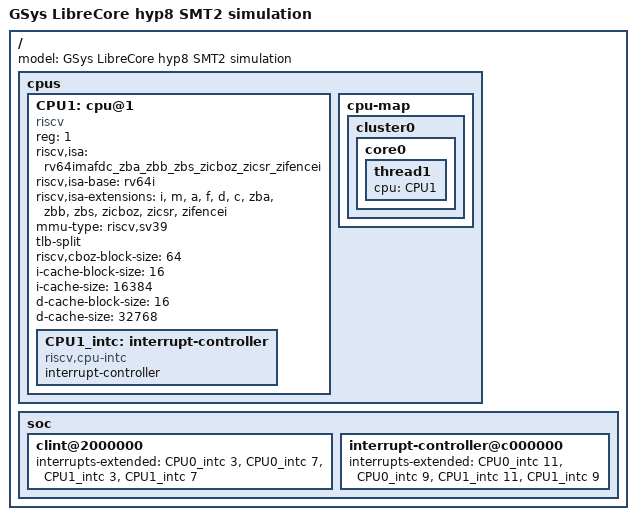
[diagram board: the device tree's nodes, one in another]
// Copyright (c) 2026 Etienne Cimon
// SPDX-License-Identifier: MIT
/dts-v1/;
/include/ "g6lc-hyp8-platform.dtsi"

/ {
    model = "GSys LibreCore hyp8 SMT2 simulation";
    cpus {
        CPU1: cpu@1 {
            device_type = "cpu";
            compatible = "riscv";
            reg = <1>;
            status = "okay";
            riscv,isa = "rv64imafdc_zba_zbb_zbs_zicboz_zicsr_zifencei";
            riscv,isa-base = "rv64i";
            riscv,isa-extensions = "i", "m", "a", "f", "d", "c",
                                  "zba", "zbb", "zbs", "zicboz",
                                  "zicsr", "zifencei";
            mmu-type = "riscv,sv39";
            tlb-split;
            riscv,cboz-block-size = <64>;
            i-cache-block-size = <16>;
            i-cache-size = <16384>;
            d-cache-block-size = <16>;
            d-cache-size = <32768>;
            CPU1_intc: interrupt-controller {
                #address-cells = <0>;
                #interrupt-cells = <1>;
                interrupt-controller;
                compatible = "riscv,cpu-intc";
            };
        };
        cpu-map {
            cluster0 {
                core0 {
                    thread1 { cpu = <&CPU1>; };
                };
            };
        };
    };
    soc {
        clint@2000000 {
            interrupts-extended = <&CPU0_intc 3>, <&CPU0_intc 7>,
                                  <&CPU1_intc 3>, <&CPU1_intc 7>;
        };
        interrupt-controller@c000000 {
            interrupts-extended = <&CPU0_intc 11>, <&CPU0_intc 9>,
                                  <&CPU1_intc 11>, <&CPU1_intc 9>;
        };
    };
};
